# ballast register map
Vendor: tuni.fi; File version: 1.0
CPU: other, little endian, MPU, FPU, vendor SysTick, 3 interrupt priority bits
Registers are 32-bit, read-write, no defined reset value unless marked. A register's access mark holds for its fields unless they carry their own. Offsets are from the block's base; [hi:lo] are bit positions; lines under a group give offsets from that group; {n}, {i} and the like mark numbered series; 'fields as' and 'values as' point back to an identical list.

## AI
Base 0x10F000000
0x00 CFGROM group
  0x00 HW_VERSION_0 ro reset 0x10001
    [31:0] HW_VERSION
  0x04 GLB_DESC_0 ro reset 0x1
    [31:0] GLB_DESC
  0x08 CIF_DESC_0 ro reset 0x180002 (reset mask 0x7FFFFFF)
    [31:0] CIF_DESC
  0x0C CIF_CAP_INCOMPAT_0 ro reset 0x0
    [31:0] CIF_CAP_INCOMPAT
  0x10 CIF_CAP_COMPAT_0 ro reset 0x0 (reset mask 0x1FFF)
    [31:0] CIF_CAP_COMPAT
  0x14 CIF_BASE_WIDTH_0 ro reset 0x8 (reset mask 0xF)
    [7:0] CIF_BASE_WIDTH
  0x18 CIF_BASE_LATENCY_0 ro reset 0x32 (reset mask 0xFFFF)
    [31:0] CIF_BASE_LATENCY
  0x1C CIF_BASE_BURST_LENGTH_MAX_0 ro reset 0x80 (reset mask 0x1FE0)
    [31:5] BASE_BURST_LENGTH_MAX
  0x20 CIF_BASE_MEM_ADDR_WIDTH_0 ro reset 0x400 (reset mask 0x1FE0)
    [31:5] CIF_BASE_MEM_ADDR_WIDTH
  0x24 CDMA_DESC_0 ro reset 0x340003
    [31:0] CDMA_DESC
  0x28 CDMA_CAP_INCOMPAT_0 ro reset 0x0
    [31:0] CDMA_CAP_INCOMPAT
  0x2C CDMA_CAP_COMPAT_0 ro reset 0x10
    [31:0] CDMA_CAP_COMPAT
  0x30 CDMA_BASE_FEATURE_TYPES_0 ro reset 0x10
    [11:0] CDMA_BASE_FEATURE_TYPES
  0x34 CDMA_BASE_WEIGHT_TYPES_0 ro reset 0x10
    [11:0] CDMA_BASE_WEIGHT_TYPES
  0x38 CDMA_BASE_ATOMIC_C_0 ro reset 0x8 (reset mask 0xFF)
    [31:0] CDMA_BASE_ATOMIC_C
  0x3C CDMA_BASE_ATOMIC_K_0 ro reset 0x8 (reset mask 0xFF)
    [31:0] CDMA_BASE_ATOMIC_K
  0x40 CDMA_BASE_ATOMIC_M_0 ro reset 0x8 (reset mask 0xFF)
    [31:0] CDMA_BASE_ATOMIC_M
  0x44 CDMA_BASE_CBUF_BANK_NUM_0 ro reset 0x20
    [31:0] CDMA_BASE_CBUF_BANK_NUM
  0x48 CDMA_BASE_CBUF_BANK_WIDTH_0 ro reset 0x8
    [31:0] CDMA_BASE_CBUF_BANK_WIDTH
  0x4C CDMA_BASE_CBUF_BANK_DEPTH_0 ro reset 0x200
    [31:0] CDMA_BASE_CBUF_BANK_DEPTH
  0x50 CDMA_MULTI_BATCH_MAX_0 ro reset 0x0
    [31:0] CDMA_MULTI_BATCH_MAX
  0x54 CDMA_IMAGE_IN_FORMATS_PACKED_0 ro reset 0xCFFF001
    [31:0] CDMA_IMAGE_IN_FORMATS_PACKED
  0x58 CDMA_IMAGE_IN_FORMATS_SEMI_0 ro reset 0x3
    [31:0] CDMA_IMAGE_IN_FORMATS_SEMI
  0x5C CBUF_DESC_0 ro reset 0x180004
    [31:0] CBUF_DESC
  0x60 CBUF_CAP_INCOMPAT_0 ro reset 0x0
    [31:0] CBUF_CAP_INCOMPAT
  0x64 CBUF_CAP_COMPAT_0 ro reset 0x0
    [31:0] CBUF_CAP_COMPAT
  0x68 CBUF_BASE_CBUF_BANK_NUM_0 ro reset 0x20
    [31:0] CBUF_BASE_CBUF_BANK_NUM
  0x6C CBUF_BASE_CBUF_BANK_WIDTH_0 ro reset 0x8
    [31:0] CBUF_BASE_CBUF_BANK_WIDTH
  0x70 CBUF_BASE_CBUF_BANK_DEPTH_0 ro reset 0x200
    [31:0] CBUF_BASE_CBUF_BANK_DEPTH
  0x74 CBUF_BASE_CDMA_ID_0 ro reset 0x3
    [31:0] CBUF_BASE_CDMA_ID
  0x78 CSC_DESC_0 ro reset 0x300005
    [31:0] CSC_DESC
  0x7C CSC_CAP_INCOMPAT_0 ro reset 0x0
    [31:0] CSC_CAP_INCOMPAT
  0x80 CSC_CAP_COMPAT_0 ro reset 0x10
    [31:0] CSC_CAP_COMPAT
  0x84 CSC_BASE_FEATURE_TYPES_0 ro reset 0x10
    [11:0] CSC_BASE_FEATURE_TYPES
  0x88 CSC_BASE_WEIGHT_TYPES_0 ro reset 0x10
    [11:0] CSC_BASE_WEIGHT_TYPES
  0x8C CSC_BASE_ATOMIC_C_0 ro reset 0x8 (reset mask 0xFF)
    [31:0] CSC_BASE_ATOMIC_C
  0x90 CSC_BASE_ATOMIC_K_0 ro reset 0x8 (reset mask 0xFF)
    [31:0] CSC_BASE_ATOMIC_K
  0x94 CSC_BASE_ATOMIC_M_0 ro reset 0x8 (reset mask 0xFF)
    [31:0] CSC_BASE_ATOMIC_M
  0x98 CSC_BASE_CBUF_BANK_NUM_0 ro reset 0x20
    [31:0] CSC_BASE_CBUF_BANK_NUM
  0x9C CSC_BASE_CBUF_BANK_WIDTH_0 ro reset 0x8
    [31:0] CSC_BASE_CBUF_BANK_WIDTH
  0xA0 CSC_BASE_CBUF_BANK_DEPTH_0 ro reset 0x200
    [31:0] CSC_BASE_CBUF_BANK_DEPTH
  0xA4 CSC_BASE_CDMA_ID_0 ro reset 0x3
    [31:0] CSC_BASE_CDMA_ID
  0xA8 CSC_MULTI_BATCH_MAX_0 ro reset 0x0
    [31:0] CSC_MULTI_BATCH_MAX
  0xAC CMAC_A_DESC_0 ro reset 0x1C0006
    [31:0] CMAC_A_DESC
  0xB0 CMAC_A_CAP_INCOMPAT_0 ro reset 0x0
    [31:0] CMAC_A_CAP_INCOMPAT
  0xB4 CMAC_A_CAP_COMPAT_0 ro reset 0x10
    [31:0] CMAC_A_CAP_COMPAT
  0xB8 CMAC_A_BASE_FEATURE_TYPES_0 ro reset 0x10
    [11:0] CMAC_A_BASE_FEATURE_TYPES
  0xBC CMAC_A_BASE_WEIGHT_TYPES_0 ro reset 0x10
    [11:0] CMAC_A_BASE_WEIGHT_TYPES
  0xC0 CMAC_A_BASE_ATOMIC_C_0 ro reset 0x8 (reset mask 0xFF)
    [31:0] CMAC_A_BASE_ATOMIC_C
  0xC4 CMAC_A_BASE_ATOMIC_K_0 ro reset 0x8 (reset mask 0xFF)
    [31:0] CMAC_A_BASE_ATOMIC_K
  0xC8 CMAC_A_BASE_CDMA_ID_0 ro reset 0x3
    [31:0] CMAC_A_BASE_CDMA_ID
  0xCC CMAC_B_DESC_0 ro reset 0x1C0006
    [31:0] CMAC_B_DESC
  0xD0 CMAC_B_CAP_INCOMPAT_0 ro reset 0x0
    [31:0] CMAC_B_CAP_INCOMPAT
  0xD4 CMAC_B_CAP_COMPAT_0 ro reset 0x10
    [31:0] CMAC_B_CAP_COMPAT
  0xD8 CMAC_B_BASE_FEATURE_TYPES_0 ro reset 0x10
    [11:0] CMAC_B_BASE_FEATURE_TYPES
  0xDC CMAC_B_BASE_WEIGHT_TYPES_0 ro reset 0x10
    [11:0] CMAC_B_BASE_WEIGHT_TYPES
  0xE0 CMAC_B_BASE_ATOMIC_C_0 ro reset 0x8 (reset mask 0xFF)
    [31:0] CMAC_B_BASE_ATOMIC_C
  0xE4 CMAC_B_BASE_ATOMIC_K_0 ro reset 0x8 (reset mask 0xFF)
    [31:0] CMAC_B_BASE_ATOMIC_K
  0xE8 CMAC_B_BASE_CDMA_ID_0 ro reset 0x3
    [31:0] CMAC_B_BASE_CDMA_ID
  0xEC CACC_DESC_0 ro reset 0x200007
    [31:0] CACC_DESC
  0xF0 CACC_CAP_INCOMPAT_0 ro reset 0x0
    [31:0] CACC_CAP_INCOMPAT
  0xF4 CACC_CAP_COMPAT_0 ro reset 0x0
    [31:0] CACC_CAP_COMPAT
  0xF8 CACC_BASE_FEATURE_TYPES_0 ro reset 0x10
    [11:0] CACC_BASE_FEATURE_TYPES
  0xFC CACC_BASE_WEIGHT_TYPES_0 ro reset 0x10
    [11:0] CACC_BASE_WEIGHT_TYPES
  0x100 CACC_BASE_ATOMIC_C_0 ro reset 0x8 (reset mask 0xFF)
    [31:0] CACC_BASE_ATOMIC_C
  0x104 CACC_BASE_ATOMIC_K_0 ro reset 0x8 (reset mask 0xFF)
    [31:0] CACC_BASE_ATOMIC_K
  0x108 CACC_BASE_CDMA_ID_0 ro reset 0x3
    [31:0] CACC_BASE_CDMA_ID
  0x10C CACC_MULTI_BATCH_MAX_0 ro reset 0x0
    [31:0] CACC_MULTI_BATCH_MAX
  0x110 SDP_RDMA_DESC_0 ro reset 0xE0008
    [31:0] SDP_RDMA_DESC
  0x114 SDP_RDMA_CAP_INCOMPAT_0 ro reset 0x0
    [31:0] SDP_RDMA_CAP_INCOMPAT
  0x118 SDP_RDMA_CAP_COMPAT_0 ro reset 0x0
    [31:0] SDP_RDMA_CAP_COMPAT
  0x11C SDP_RDMA_BASE_ATOMIC_M_0 ro reset 0x8 (reset mask 0xFF)
    [31:0] SDP_RDMA_BASE_ATOMIC_M
  0x120 SDP_RDMA_BASE_SDP_ID_0 ro reset 0x9
    [31:0] SDP_RDMA_BASE_SDP_ID
  0x124 SDP_DESC_0 ro reset 0x200009
    [31:0] SDP_DESC
  0x128 SDP_CAP_INCOMPAT_0 ro reset 0x0
    [31:0] SDP_CAP_INCOMPAT
  0x12C SDP_CAP_COMPAT_0 ro reset 0x18
    [31:0] SDP_CAP_COMPAT
  0x130 SDP_BASE_FEATURE_TYPES_0 ro reset 0x10
    [11:0] SDP_BASE_FEATURE_TYPES
  0x134 SDP_BASE_WEIGHT_TYPES_0 ro reset 0x10
    [11:0] SDP_BASE_WEIGHT_TYPES
  0x138 SDP_BASE_CDMA_ID_0 ro reset 0x3
    [31:0] SDP_BASE_CDMA_ID
  0x13C SDP_MULTI_BATCH_MAX_0 ro reset 0x0
    [31:0] SDP_MULTI_BATCH_MAX
  0x140 SDP_BS_THROUGHPUT_0 ro reset 0x1
    [31:0] SDP_BS_THROUGHPUT
  0x144 SDP_BN_THROUGHPUT_0 ro reset 0x1
    [31:0] SDP_BN_THROUGHPUT
  0x148 SDP_EW_THROUGHPUT_0 ro reset 0x0
    [31:0] SDP_EW_THROUGHPUT
  0x14C PDP_RDMA_DESC_0 ro reset 0xE000A
    [31:0] PDP_RDMA_DESC
  0x150 PDP_RDMA_CAP_INCOMPAT_0 ro reset 0x0
    [31:0] PDP_RDMA_CAP_INCOMPAT
  0x154 PDP_RDMA_CAP_COMPAT_0 ro reset 0x0
    [31:0] PDP_RDMA_CAP_COMPAT
  0x158 PDP_RDMA_BASE_ATOMIC_M_0 ro reset 0x8 (reset mask 0xFF)
    [31:0] PDP_RDMA_BASE_ATOMIC_M
  0x15C PDP_RDMA_BASE_PDP_ID_0 ro reset 0xB
    [31:0] PDP_RDMA_BASE_PDP_ID
  0x160 PDP_DESC_0 ro reset 0x10000B
    [31:0] PDP_DESC
  0x164 PDP_CAP_INCOMPAT_0 ro reset 0x0
    [31:0] PDP_CAP_INCOMPAT
  0x168 PDP_CAP_COMPAT_0 ro reset 0x0
    [31:0] PDP_CAP_COMPAT
  0x16C PDP_BASE_FEATURE_TYPES_0 ro reset 0x10
    [11:0] PDP_BASE_FEATURE_TYPES
  0x170 PDP_BASE_THROUGHPUT_0 ro reset 0x1
    [31:0] PDP_BASE_THROUGHPUT
  0x174 CDP_RDMA_DESC_0 ro reset 0xE000C
    [31:0] CDP_RDMA_DESC
  0x178 CDP_RDMA_CAP_INCOMPAT_0 ro reset 0x0
    [31:0] CDP_RDMA_CAP_INCOMPAT
  0x17C CDP_RDMA_CAP_COMPAT_0 ro reset 0x0
    [31:0] CDP_RDMA_CAP_COMPAT
  0x180 CDP_RDMA_BASE_ATOMIC_M_0 ro reset 0x8 (reset mask 0xFF)
    [31:0] CDP_RDMA_BASE_ATOMIC_M
  0x184 CDP_RDMA_BASE_CDP_ID_0 ro reset 0xD
    [31:0] CDP_RDMA_BASE_CDP_ID
  0x188 CDP_DESC_0 ro reset 0x10000D
    [31:0] CDP_DESC
  0x18C CDP_CAP_INCOMPAT_0 ro reset 0x0
    [31:0] CDP_CAP_INCOMPAT
  0x190 CDP_CAP_COMPAT_0 ro reset 0x0
    [31:0] CDP_CAP_COMPAT
  0x194 CDP_BASE_FEATURE_TYPES_0 ro reset 0x10
    [11:0] CDP_BASE_FEATURE_TYPES
  0x198 CDP_BASE_THROUGHPUT_0 ro reset 0x1
    [31:0] CDP_BASE_THROUGHPUT
  0x19C END_OF_LIST_0 ro reset 0x0
    [31:0] END_OF_LIST
0x1000 GLB group
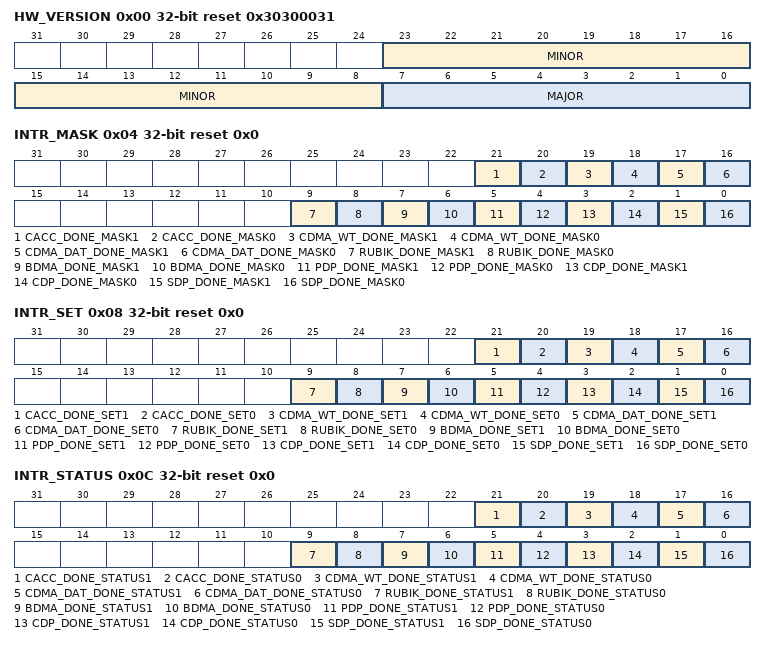
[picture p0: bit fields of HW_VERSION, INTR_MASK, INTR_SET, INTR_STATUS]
  0x00 HW_VERSION ro reset 0x30300031 (reset mask 0xFFFF00FF) — HW version of NVDLA
    [23:8] MINOR, [7:0] MAJOR
  0x04 INTR_MASK reset 0x0 (reset mask 0xFC000C03) — Interrupt mask control
    [21] CACC_DONE_MASK1 rw-once, [20] CACC_DONE_MASK0 rw-once, [19] CDMA_WT_DONE_MASK1 rw-once, [18] CDMA_WT_DONE_MASK0 rw-once, [17] CDMA_DAT_DONE_MASK1 rw-once, [16] CDMA_DAT_DONE_MASK0 rw-once, [9] RUBIK_DONE_MASK1 rw-once, [8] RUBIK_DONE_MASK0 rw-once, [7] BDMA_DONE_MASK1 rw-once, [6] BDMA_DONE_MASK0 rw-once, [5] PDP_DONE_MASK1 rw-once, [4] PDP_DONE_MASK0 rw-once, [3] CDP_DONE_MASK1 rw-once, [2] CDP_DONE_MASK0 rw-once, [1] SDP_DONE_MASK1 rw-once, [0] SDP_DONE_MASK0 rw-once
  0x08 INTR_SET wo reset 0x0 (reset mask 0xFC000C03) — Interrupt set control
    [21] CACC_DONE_SET1, [20] CACC_DONE_SET0, [19] CDMA_WT_DONE_SET1, [18] CDMA_WT_DONE_SET0, [17] CDMA_DAT_DONE_SET1, [16] CDMA_DAT_DONE_SET0, [9] RUBIK_DONE_SET1, [8] RUBIK_DONE_SET0, [7] BDMA_DONE_SET1, [6] BDMA_DONE_SET0, [5] PDP_DONE_SET1, [4] PDP_DONE_SET0, [3] CDP_DONE_SET1, [2] CDP_DONE_SET0, [1] SDP_DONE_SET1, [0] SDP_DONE_SET0
  0x0C INTR_STATUS reset 0x0 (reset mask 0xFC000C03) — Interrupt status
    [21] CACC_DONE_STATUS1 rw-once, [20] CACC_DONE_STATUS0 rw-once, [19] CDMA_WT_DONE_STATUS1 rw-once, [18] CDMA_WT_DONE_STATUS0 rw-once, [17] CDMA_DAT_DONE_STATUS1 rw-once, [16] CDMA_DAT_DONE_STATUS0 rw-once, [9] RUBIK_DONE_STATUS1 rw-once, [8] RUBIK_DONE_STATUS0 rw-once, [7] BDMA_DONE_STATUS1 rw-once, [6] BDMA_DONE_STATUS0 rw-once, [5] PDP_DONE_STATUS1 rw-once, [4] PDP_DONE_STATUS0 rw-once, [3] CDP_DONE_STATUS1 rw-once, [2] CDP_DONE_STATUS0 rw-once, [1] SDP_DONE_STATUS1 rw-once, [0] SDP_DONE_STATUS0 rw-once
0x2000 MCIF group
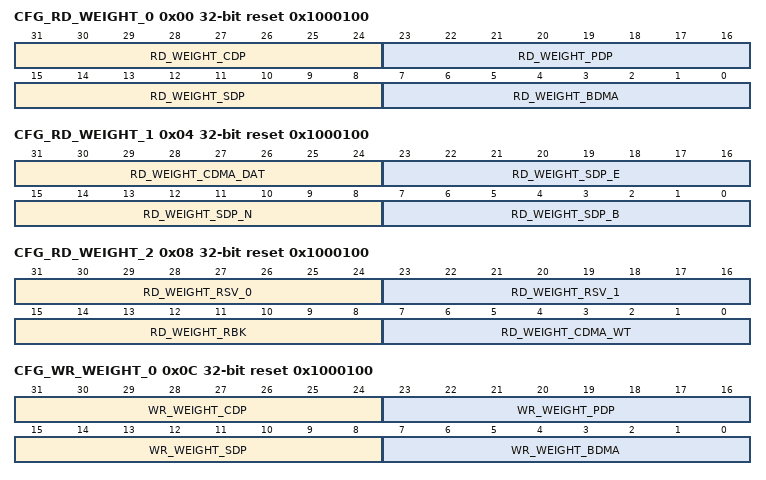
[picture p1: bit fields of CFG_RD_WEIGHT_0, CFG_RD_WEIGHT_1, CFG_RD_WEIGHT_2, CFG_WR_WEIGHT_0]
  0x00 CFG_RD_WEIGHT_0 reset 0x1000100 (reset mask 0xFF00FF00) — Register0 to control the read weight of clients in MCIF
    [31:24] RD_WEIGHT_CDP ro, [23:16] RD_WEIGHT_PDP ro, [15:8] RD_WEIGHT_SDP ro, [7:0] RD_WEIGHT_BDMA ro
  0x04 CFG_RD_WEIGHT_1 reset 0x1000100 (reset mask 0xFF00FF00) — Register1 to control the read weight of clients in MCIF
    [31:24] RD_WEIGHT_CDMA_DAT ro, [23:16] RD_WEIGHT_SDP_E ro, [15:8] RD_WEIGHT_SDP_N ro, [7:0] RD_WEIGHT_SDP_B ro
  0x08 CFG_RD_WEIGHT_2 reset 0x1000100 (reset mask 0xFF00FF00) — Register2 to control the read weight of clients in MCIF
    [31:24] RD_WEIGHT_RSV_0 ro, [23:16] RD_WEIGHT_RSV_1 ro, [15:8] RD_WEIGHT_RBK ro, [7:0] RD_WEIGHT_CDMA_WT ro
  0x0C CFG_WR_WEIGHT_0 reset 0x1000100 (reset mask 0xFF00FF00) — Register0 to control the write weight of clients in MCIF
    [31:24] WR_WEIGHT_CDP ro, [23:16] WR_WEIGHT_PDP ro, [15:8] WR_WEIGHT_SDP ro, [7:0] WR_WEIGHT_BDMA ro
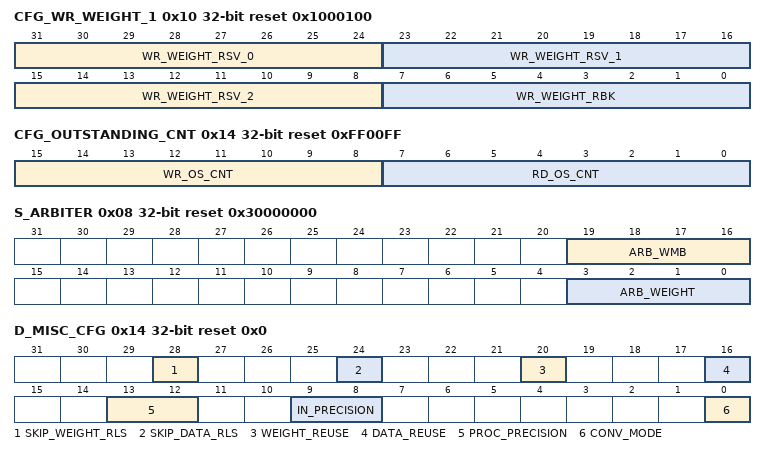
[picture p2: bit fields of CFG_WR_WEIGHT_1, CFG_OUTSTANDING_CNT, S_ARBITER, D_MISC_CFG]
  0x10 CFG_WR_WEIGHT_1 reset 0x1000100 (reset mask 0xFF00FF00) — Register1 to control the write weight of clients in MCIF
    [31:24] WR_WEIGHT_RSV_0 ro, [23:16] WR_WEIGHT_RSV_1 ro, [15:8] WR_WEIGHT_RSV_2 ro, [7:0] WR_WEIGHT_RBK ro
  0x14 CFG_OUTSTANDING_CNT reset 0xFF00FF (reset mask 0xFF00FF) — Outstanding AXI transactions in unit of 64Byte
    [15:8] WR_OS_CNT ro, [7:0] RD_OS_CNT ro
  0x18 STATUS ro reset 0x10000 (reset mask 0x10000) — Idle status of MCIF
    [8] IDLE
      0=NO; 1=YES
0x3000 CDMA group
  0x00 S_STATUS ro reset 0x0 (reset mask 0xC0000000) — Idle status of two register groups
    [17:16] STATUS_1
      1=RUNNING; 2=PENDING; 0=IDLE
    [1:0] STATUS_0
      0=IDLE; 1=RUNNING; 2=PENDING
  0x04 S_POINTER reset 0x0 (reset mask 0x80000000) — Pointer for CSB master and data path to access groups
    [16] CONSUMER ro
      1=GROUP_1; 0=GROUP_0
    [0] PRODUCER rw-once
      0=GROUP_0; 1=GROUP_1
  0x08 S_ARBITER reset 0x30000000 (reset mask 0xF0000000) — WMB and Weight share same port to access external memory. This register controls the weight factor in the arbiter.
    [19:16] ARB_WMB rw-once, [3:0] ARB_WEIGHT rw-once
  0x0C S_CBUF_FLUSH_STATUS ro reset 0x0 — Indicates whether CBUF flush is finished after reset.
    [0] FLUSH_DONE
  0x10 D_OP_ENABLE reset 0x0 — Set it to 1 to kick off operation for current register group
    [0] OP_EN rw-once
      0=DISABLE; 1=ENABLE
  0x14 D_MISC_CFG reset 0x0 (reset mask 0x88008801) — Configuration of operation: convolution mode, precision, weight reuse, data reuse.
    [28] SKIP_WEIGHT_RLS rw-once
      1=ENABLE; 0=DISABLE
    [24] SKIP_DATA_RLS rw-once
      1=ENABLE; 0=DISABLE
    [20] WEIGHT_REUSE rw-once
      1=ENABLE; 0=DISABLE
    [16] DATA_REUSE rw-once
      1=ENABLE; 0=DISABLE
    [13:12] PROC_PRECISION rw-once
      2=FP16; 1=INT16; 0=INT8
    [9:8] IN_PRECISION rw-once
      0=INT8; 1=INT16; 2=FP16
    [0] CONV_MODE rw-once
      0=DIRECT; 1=WINOGRAD
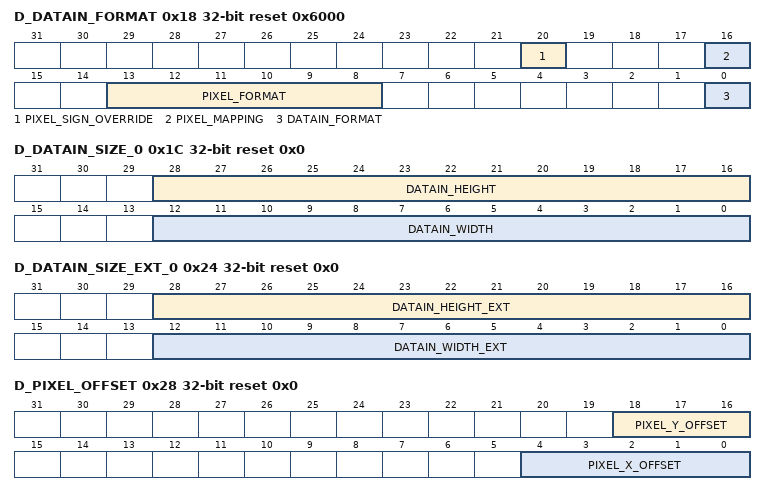
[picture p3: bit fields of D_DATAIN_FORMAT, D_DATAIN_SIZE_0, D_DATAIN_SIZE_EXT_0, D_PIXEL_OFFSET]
  0x18 D_DATAIN_FORMAT reset 0x6000 (reset mask 0x8801F800) — Input data format and pixel format
    [20] PIXEL_SIGN_OVERRIDE rw-once
      0=UNSIGNED_INT; 1=SIGNED_INT
    [16] PIXEL_MAPPING rw-once
      0=PITCH_LINEAR
    [13:8] PIXEL_FORMAT rw-once
      0=T_R8; 1=T_R10; 2=T_R12; 3=T_R16; 4=T_R16_I; 5=T_R16_F; 6=T_A16B16G16R16; 7=T_X16B16G16R16; 8=T_A16B16G16R16_F; 9=T_A16Y16U16V16; 10=T_V16U16Y16A16; 11=T_A16Y16U16V16_F; 12=T_A8B8G8R8; 31=T_Y10___V10U10_N444; 19=T_R8G8B8X8; 13=T_A8R8G8B8; 26=T_A8Y8U8V8; 18=T_B8G8R8X8; 32=T_Y12___U12V12_N444; 20=T_A2B10G10R10; 14=T_B8G8R8A8; 33=T_Y12___V12U12_N444; 21=T_A2R10G10B10; 15=T_R8G8B8A8; 34=T_Y16___U16V16_N444; 22=T_B10G10R10A2; 27=T_V8U8Y8A8; 16=T_X8B8G8R8; 35=T_Y16___V16U16_N444; 23=T_R10G10B10A2; 28=T_Y8___U8V8_N444; 29=T_Y8___V8U8_N444; 30=T_Y10___U10V10_N444; 17=T_X8R8G8B8; 24=T_A2Y10U10V10; 25=T_V10U10Y10A2
    [0] DATAIN_FORMAT rw-once
      1=PIXEL; 0=FEATURE
  0x1C D_DATAIN_SIZE_0 reset 0x0 (reset mask 0xFFF80000) — Input cube’s width and height
    [28:16] DATAIN_HEIGHT rw-once, [12:0] DATAIN_WIDTH rw-once
  0x20 D_DATAIN_SIZE_1 reset 0x0 — Input cube’s channel
    [12:0] DATAIN_CHANNEL rw-once
  0x24 D_DATAIN_SIZE_EXT_0 reset 0x0 (reset mask 0xFFF80000) — Input cube’s width and height after extension
    [28:16] DATAIN_HEIGHT_EXT, [12:0] DATAIN_WIDTH_EXT
  0x28 D_PIXEL_OFFSET reset 0x0 (reset mask 0xE0000003) — For image-in mode, horizontal offset and vertical offset of the 1 st pixel.
    [18:16] PIXEL_Y_OFFSET rw-once, [4:0] PIXEL_X_OFFSET rw-once
  0x2C D_DAIN_RAM_TYPE reset 0x0 — Ram type of input RAM
    [0] DATAIN_RAM_TYPE rw-once
      0=CVIF; 1=MCIF
  0x30 D_DAIN_ADDR_HIGH_0 reset 0x0 — Higher 32bits of input data address when axi araddr is 64bits
    [31:0] DATAIN_ADDR_HIGH_0 rw-once
  0x34 D_DAIN_ADDR_LOW_0 reset 0x0 — Lower 32bits of input data address
    [31:0] DATAIN_ADDR_LOW_0
  0x38 D_DAIN_ADDR_HIGH_1 reset 0x0 — Higher 32bits of input data address of UV plane when axi araddr is 64bits
    [31:0] DATAIN_ADDR_HIGH_1
  0x3C D_DAIN_ADDR_LOW_1 reset 0x0 — Lower 32bits of input data address of UV plane
    [31:0] DATAIN_ADDR_LOW_1
  0x40 D_LINE_STRIDE reset 0x0 — Line stride of input cube
    [31:0] LINE_STRIDE
  0x44 D_LINE_UV_STRIDE reset 0x0 — Line stride of input cube’s UV plane
    [31:0] UV_LINE_STRIDE
  0x48 D_SURF_STRIDE reset 0x0 — Surface stride of input cube
    [31:0] SURF_STRIDE
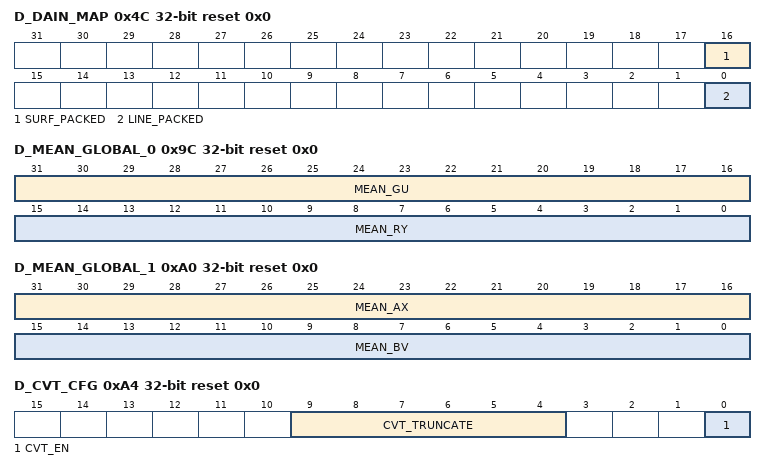
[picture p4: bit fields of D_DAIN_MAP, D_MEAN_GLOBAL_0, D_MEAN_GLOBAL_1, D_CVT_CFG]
  0x4C D_DAIN_MAP reset 0x0 (reset mask 0x80000000) — Whether input cube is line packed or surface packed
    [16] SURF_PACKED
      1=TRUE; 0=FALSE
    [0] LINE_PACKED
      0=FALSE; 1=TRUE
  0x58 D_BATCH_NUMBER reset 0x0 — Number of batches
    [4:0] BATCHES
  0x5C D_BATCH_STRIDE reset 0x0 — The stride of input data cubes when batches > 1
    [31:0] BATCH_STRIDE
  0x60 D_ENTRY_PER_SLICE reset 0x0 — Number of CBUF entries used for one input slice
    [13:0] ENTRIES
  0x64 D_FETCH_GRAIN reset 0x0 — Number of slices to be fetched before sending update information to CSC
    [11:0] GRAINS
  0x68 D_WEIGHT_FORMAT reset 0x0 — Whether weight is compressed or not
    [0] WEIGHT_FORMAT
      1=COMPRESSED; 0=UNCOMPRESSED
  0x6C D_WEIGHT_SIZE_0 reset 0x0 — The size of one kernel in bytes
    [17:0] BYTE_PER_KERNEL
  0x70 D_WEIGHT_SIZE_1 reset 0x0 — Number of kernels
    [12:0] WEIGHT_KERNEL
  0x74 D_WEIGHT_RAM_TYPE reset 0x0 — Ram type of weight
    [0] WEIGHT_RAM_TYPE
      1=MCIF; 0=CVIF
  0x78 D_WEIGHT_ADDR_HIGH reset 0x0 — Higher 32bits of weight address when axi araddr is 64bits
    [31:0] WEIGHT_ADDR_HIGH
  0x7C D_WEIGHT_ADDR_LOW reset 0x0 — Lower 32bits of weight address
    [31:0] WEIGHT_ADDR_LOW
  0x80 D_WEIGHT_BYTES reset 0x0 (reset mask 0x1FFFFFF) — Total bytes of Weight
    [31:0] WEIGHT_BYTES
  0x84 D_WGS_ADDR_HIGH reset 0x0 — Higher 32bits of wgs address when axi araddr is 64bits
    [31:0] WGS_ADDR_HIGH
  0x88 D_WGS_ADDR_LOW reset 0x0 — Lower 32bits of wgs address
    [31:0] WGS_ADDR_LOW
  0x8C D_WMB_ADDR_HIGH reset 0x0 — Higher 32bits of wmb address when axi araddr is 64bits
    [31:0] WMB_ADDR_HIGH
  0x90 D_WMB_ADDR_LOW reset 0x0 — Lower 32bits of wmb address
    [31:0] WMB_ADDR_LOW
  0x94 D_WMB_BYTES reset 0x0 (reset mask 0x1FFFFF) — Total bytes of WMB
    [27:0] WMB_BYTES
  0x98 D_MEAN_FORMAT reset 0x0 — Whether mean registers are used or not
    [0] MEAN_FORMAT
      1=ENABLE; 0=DISABLE
  0x9C D_MEAN_GLOBAL_0 reset 0x0 (reset mask 0xFFFF0000) — Global mean value for red in RGB or Y in YUV Global mean value for green in RGB or U in YUV
    [31:16] MEAN_GU, [15:0] MEAN_RY
  0xA0 D_MEAN_GLOBAL_1 reset 0x0 (reset mask 0xFFFF0000) — Global mean value for blue in RGB or V in YUV Global mean value for alpha in ARGB/AYUV or X in XRGB
    [31:16] MEAN_AX, [15:0] MEAN_BV
  0xA4 D_CVT_CFG reset 0x0 — Enable/disable input data converter in CDMA and number of bits to be truncated in the input data converter
    [9:4] CVT_TRUNCATE
    [0] CVT_EN
      1=ENABLE; 0=DISABLE
  0xA8 D_CVT_OFFSET reset 0x0 — Offset of input data convertor
    [15:0] CVT_OFFSET
  0xAC D_CVT_SCALE reset 0x0 — Scale of input data convertor
    [15:0] CVT_SCALE
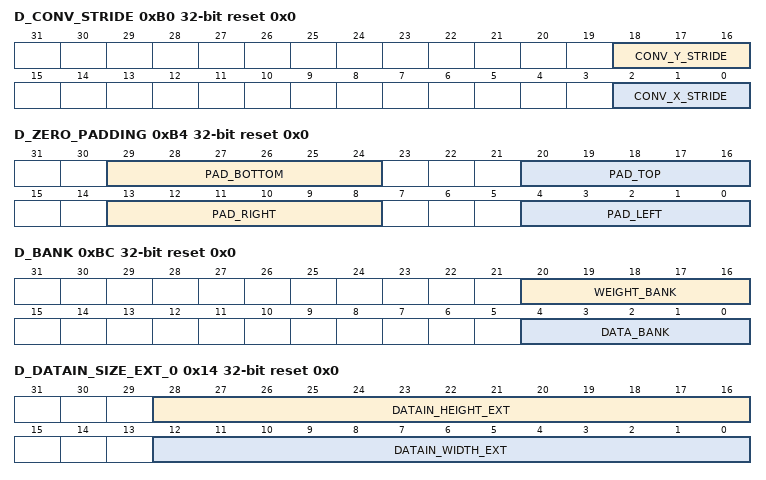
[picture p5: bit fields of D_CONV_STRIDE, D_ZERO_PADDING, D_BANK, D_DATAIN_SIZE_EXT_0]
  0xB0 D_CONV_STRIDE reset 0x0 (reset mask 0xE0000000) — Convolution x stride and convolution y stride
    [18:16] CONV_Y_STRIDE, [2:0] CONV_X_STRIDE
  0xB4 D_ZERO_PADDING reset 0x0 (reset mask 0xFC007C00) — Left/right/top/bottom padding size
    [29:24] PAD_BOTTOM, [20:16] PAD_TOP, [13:8] PAD_RIGHT, [4:0] PAD_LEFT
  0xB8 D_ZERO_PADDING_VALUE reset 0x0 — Padding value
    [15:0] PAD_VALUE
  0xBC D_BANK reset 0x0 (reset mask 0xF8000000) — Number of data banks and weight banks in CBUF
    [20:16] WEIGHT_BANK, [4:0] DATA_BANK
  0xC0 D_NAN_FLUSH_TO_ZERO ro reset 0x0 — Enable/Disable flushing input NaN to zero
    [0] NAN_TO_ZERO
      1=ENABLE; 0=DISABLE
  0xC4 D_NAN_INPUT_DATA_NUM ro reset 0x0 — Count NaN number in input data cube, update per layer
    [31:0] NAN_DATA_NUM
  0xC8 D_NAN_INPUT_WEIGHT_NUM ro reset 0x0 — Count NaN number in weight kernels, update per layer
    [31:0] NAN_WEIGHT_NUM
  0xCC D_INF_INPUT_DATA_NUM ro reset 0x0 — Count infinity number in input data cube, update per layer
    [31:0] INF_DATA_NUM
  0xD0 D_INF_INPUT_WEIGHT_NUM ro reset 0x0 — Count infinity number in weight kernels, update per layer
    [31:0] INF_WEIGHT_NUM
  0xD4 D_PERF_ENABLE reset 0x0 — Enable/disable performance counter
    [0] DMA_EN
  0xD8 D_PERF_DAT_READ_STALL ro reset 0x0 — Count blocking cycles of read request of input data, update per layer
    [31:0] DAT_RD_STALL
  0xDC D_PERF_WT_READ_STALL ro reset 0x0 — Count blocking cycles of read request of weight data, update per layer
    [31:0] WT_RD_STALL
  0xE0 D_PERF_DAT_READ_LATENCY ro reset 0x0 — Count total latency cycles of read response of input data, update per layer
    [31:0] DAT_RD_LATENCY
  0xE4 D_PERF_WT_READ_LATENCY ro reset 0x0 — Count total latency cycles of read request of weight data, update per layer
    [31:0] WT_RD_LATENCY
  0xE8 D_CYA reset 0x0
    [31:0] D_CYA — CYA register
0x4000 CSC group
  0x00 S_STATUS ro reset 0x0 (reset mask 0xC0000000) — Idle status of two register groups
    [17:16] STATUS_1
      1=RUNNING; 2=PENDING; 0=IDLE
    [1:0] STATUS_0
      1=RUNNING; 2=PENDING; 0=IDLE
  0x04 S_POINTER reset 0x0 (reset mask 0x80000000) — Pointer for CSB master and data path to access groups
    [16] CONSUMER ro
      1=GROUP_1; 0=GROUP_0
    [0] PRODUCER
      1=GROUP_1; 0=GROUP_0
  0x08 D_OP_ENABLE reset 0x0 — Set it to 1 to kick off operation for current register group
    [0] OP_EN
      1=ENABLE; 0=DISABLE
  0x0C D_MISC_CFG reset 0x0 (reset mask 0x88008801) — Configuration of operation: convolution mode, precision, weight reuse, data reuse.
    [28] SKIP_WEIGHT_RLS
      1=ENABLE; 0=DISABLE
    [24] SKIP_DATA_RLS
      1=ENABLE; 0=DISABLE
    [20] WEIGHT_REUSE
      1=ENABLE; 0=DISABLE
    [16] DATA_REUSE
      1=ENABLE; 0=DISABLE
    [13:12] PROC_PRECISION
      2=FP16; 1=INT16; 0=INT8
    [9:8] IN_PRECISION
      2=FP16; 1=INT16; 0=INT8
    [0] CONV_MODE
      0=DIRECT; 1=WINOGRAD
  0x10 D_DATAIN_FORMAT reset 0x0 — Input data format and pixel format
    [0] DATAIN_FORMAT
      1=PIXEL; 0=FEATURE
  0x14 D_DATAIN_SIZE_EXT_0 reset 0x0 (reset mask 0xFFF80000) — Input cube’s width and height after extension
    [28:16] DATAIN_HEIGHT_EXT, [12:0] DATAIN_WIDTH_EXT
  0x18 D_DATAIN_SIZE_EXT_1 reset 0x0 — Input cube’s channel after extension
    [12:0] DATAIN_CHANNEL_EXT
  0x1C D_BATCH_NUMBER reset 0x0 — Number of batches
    [4:0] BATCHES
  0x20 D_POST_Y_EXTENSION reset 0x0 — Post extension parameter for image-in
    [1:0] Y_EXTENSION
  0x24 D_ENTRY_PER_SLICE reset 0x0 — Number of CBUF entries used for one input slice
    [13:0] ENTRIES
  0x28 D_WEIGHT_FORMAT reset 0x0 — Whether weight is compressed or not
    [0] WEIGHT_FORMAT
      1=COMPRESSED; 0=UNCOMPRESSED
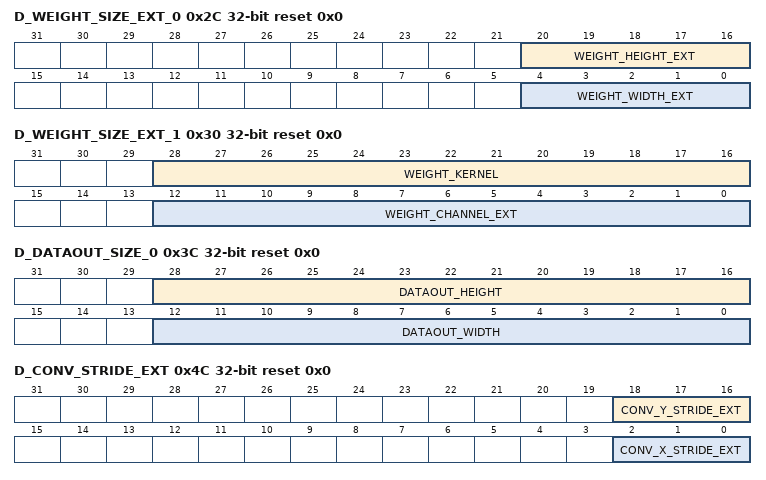
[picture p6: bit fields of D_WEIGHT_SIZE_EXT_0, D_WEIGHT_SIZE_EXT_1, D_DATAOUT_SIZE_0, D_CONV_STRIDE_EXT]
  0x2C D_WEIGHT_SIZE_EXT_0 reset 0x0 (reset mask 0xF8000000) — Weight’s width and height after extension
    [20:16] WEIGHT_HEIGHT_EXT, [4:0] WEIGHT_WIDTH_EXT
  0x30 D_WEIGHT_SIZE_EXT_1 reset 0x0 (reset mask 0xFFF80000) — Weight’s channel after extension and number of weight kernels
    [28:16] WEIGHT_KERNEL, [12:0] WEIGHT_CHANNEL_EXT
  0x34 D_WEIGHT_BYTES reset 0x0 (reset mask 0x1FFFFFF) — Total bytes of Weight
    [31:0] WEIGHT_BYTES
  0x38 D_WMB_BYTES reset 0x0 (reset mask 0x1FFFFF) — Total bytes of WMB
    [27:0] WMB_BYTES
  0x3C D_DATAOUT_SIZE_0 reset 0x0 (reset mask 0xFFF80000) — Output cube’s width and height
    [28:16] DATAOUT_HEIGHT, [12:0] DATAOUT_WIDTH
  0x40 D_DATAOUT_SIZE_1 reset 0x0 — Output cube’s channel
    [12:0] DATAOUT_CHANNEL
  0x44 D_ATOMICS reset 0x1 — Equals to output_data_cube_width * output_data_cube_height - 1
    [20:0] ATOMICS
  0x48 D_RELEASE reset 0x1 — Slices of CBUF to be released at the end of current layer
    [11:0] RLS_SLICES
  0x4C D_CONV_STRIDE_EXT reset 0x0 (reset mask 0xE0000000) — Convolution x stride and convolution y stride after extension
    [18:16] CONV_Y_STRIDE_EXT, [2:0] CONV_X_STRIDE_EXT
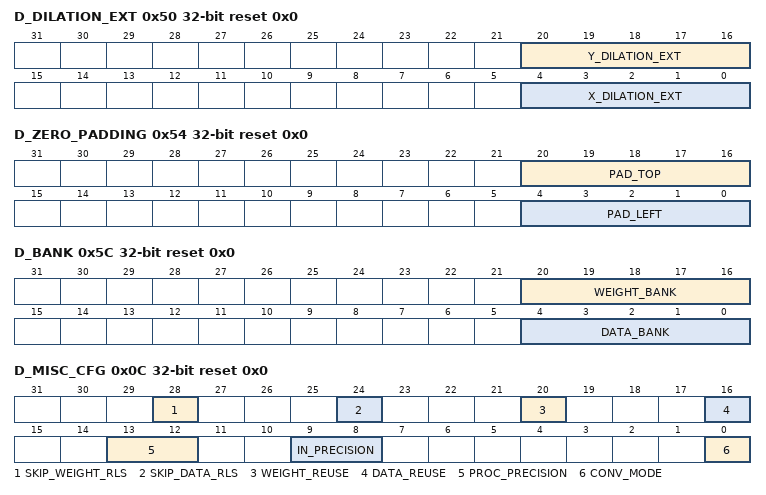
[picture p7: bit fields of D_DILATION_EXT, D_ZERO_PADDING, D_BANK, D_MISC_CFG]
  0x50 D_DILATION_EXT reset 0x0 (reset mask 0xF8000000) — Dilation parameter
    [20:16] Y_DILATION_EXT, [4:0] X_DILATION_EXT
  0x54 D_ZERO_PADDING reset 0x0 (reset mask 0xF8000000) — Left/right/top/bottom padding size
    [20:16] PAD_TOP, [4:0] PAD_LEFT
  0x58 D_ZERO_PADDING_VALUE reset 0x0 — Padding value
    [15:0] PAD_VALUE
  0x5C D_BANK reset 0x0 (reset mask 0xF8000000) — Number of data banks and weight banks in CBUF
    [20:16] WEIGHT_BANK, [4:0] DATA_BANK
  0x60 D_PRA_CFG reset 0x0 — PRA truncate in Winograd mode, range: 0~2
    [1:0] PRA_TRUNCATE
  0x64 D_CYA reset 0x0
    [31:0] D_CYA — CYA register
0x5000 CMAC_A group
  0x00 S_STATUS ro reset 0x0 (reset mask 0xC0000000) — Idle status of two register groups
    [17:16] STATUS_1
      0=IDLE; 1=RUNNING; 2=PENDING
    [1:0] STATUS_0
      0=IDLE; 1=RUNNING; 2=PENDING
  0x04 S_POINTER reset 0x0 (reset mask 0x80000000) — Pointer for CSB master and data path to access groups
    [16] CONSUMER ro
      0=GROUP_0; 1=GROUP_1
    [0] PRODUCER
      0=GROUP_0; 1=GROUP_1
  0x08 D_OP_ENABLE reset 0x0 — Set it to 1 to kick off operation for current register group
    [0] OP_EN
      1=ENABLE; 0=DISABLE
  0x0C D_MISC_CFG reset 0x100000 (reset mask 0x300001) — Configuration of operation: convolution mode, precision, etc.
    [13:12] PROC_PRECISION
      2=FP16; 1=INT16; 0=INT8
    [0] CONV_MODE
      0=DIRECT; 1=WINOGRAD
0x6000 CMAC_B group
  0x00 S_STATUS ro reset 0x0 (reset mask 0xC0000000) — Idle status of two register groups
    [17:16] STATUS_1
      1=ENABLE; 0=DISABLE
    [1:0] STATUS_0
      1=ENABLE; 0=DISABLE
  0x04 S_POINTER reset 0x0 (reset mask 0x80000000) — Pointer for CSB master and data path to access groups
    fields as CMAC_A.S_POINTER
  0x08 D_OP_ENABLE reset 0x0 — Set it to 1 to kick off operation for current register group
    [0] OP_EN
      1=ENABLE; 0=DISABLE
  0x0C D_MISC_CFG reset 0x100000 (reset mask 0x300001) — Configuration of operation: convolution mode, precision, etc.
    [13:12] PROC_PRECISION
      2=FP16; 1=INT16; 0=INT8
    [0] CONV_MODE
      1=WINOGRAD; 0=DIRECT
0x7000 CACC group
  0x00 S_STATUS ro reset 0x0 (reset mask 0xC0000000) — Idle status of two register groups
    fields as CMAC_A.S_STATUS
  0x04 S_POINTER reset 0x0 (reset mask 0x80000000) — Pointer for CSB master and data path to access groups
    fields as CMAC_A.S_POINTER
  0x08 D_OP_ENABLE reset 0x0 — Set it to 1 to kick off operation for current register group
    [0] OP_EN
      1=ENABLE; 0=DISABLE
  0x0C D_MISC_CFG reset 0x100000 (reset mask 0x300001) — Configuration of operation: convolution mode, precision, etc.
    fields as CMAC_B.D_MISC_CFG
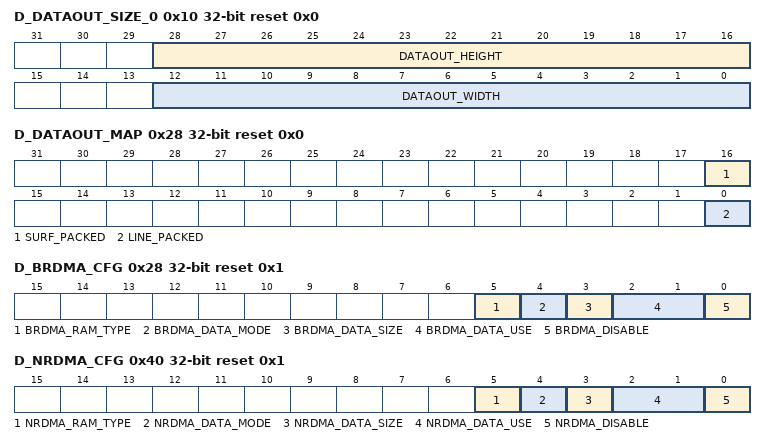
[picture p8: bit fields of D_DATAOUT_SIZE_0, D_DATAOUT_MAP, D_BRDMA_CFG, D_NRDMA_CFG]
  0x10 D_DATAOUT_SIZE_0 reset 0x0 (reset mask 0xFFF80000) — Input cube’s width and height after extension
    [28:16] DATAOUT_HEIGHT, [12:0] DATAOUT_WIDTH
  0x14 D_DATAOUT_SIZE_1 reset 0x0 — Input cube’s channel after extension
    [12:0] DATAOUT_CHANNEL
  0x18 D_DATAOUT_ADDR reset 0x0 — Address of output cube
    [31:0] DATAOUT_ADDR
  0x1C D_BATCH_NUMBER reset 0x0 — Number of batches
    [4:0] BATCHES
  0x20 D_LINE_STRIDE reset 0x0 — Line stride of output cube
    [23:0] LINE_STRIDE
  0x24 D_SURF_STRIDE reset 0x0 — Line stride of surface cube
    [23:0] SURF_STRIDE
  0x28 D_DATAOUT_MAP reset 0x0 (reset mask 0x80000000) — Whether output cube is line packed or surface packed
    [16] SURF_PACKED
      1=TRUE; 0=FALSE
    [0] LINE_PACKED
      1=TRUE; 0=FALSE
  0x2C D_CLIP_CFG reset 0x0 — Number of bits to be truncated before sending to SDP
    [4:0] CLIP_TRUNCATE
  0x30 D_OUT_SATURATION ro reset 0x0 — Output saturation count
    [31:0] SAT_COUNT
  0x34 D_CYA reset 0x0
    [31:0] D_CYA — CYA register
0x8000 SDP_RDMA group
  0x00 S_STATUS ro reset 0x0 (reset mask 0xC0000000) — Idle status of two register groups
    fields as CMAC_A.S_STATUS
  0x04 S_POINTER reset 0x0 (reset mask 0x80000000) — Pointer for CSB master and data path to access groups
    fields as CMAC_A.S_POINTER
  0x08 D_OP_ENABLE reset 0x0 — Set it to 1 to kick off operation for current register group
    [0] OP_EN
      1=ENABLE; 0=DISABLE
  0x0C D_DATA_CUBE_WIDTH reset 0x0
    [12:0] WIDTH
  0x10 D_DATA_CUBE_HEIGHT reset 0x0
    [12:0] HEIGHT
  0x14 D_DATA_CUBE_CHANNEL reset 0x0
    [12:0] CHANNEL
  0x18 D_SRC_BASE_ADDR_LOW reset 0x0
    [31:0] SRC_BASE_ADDR_LOW
  0x1C D_SRC_BASE_ADDR_HIGH reset 0x0
    [31:0] SRC_BASE_ADDR_HIGH
  0x20 D_SRC_LINE_STRIDE reset 0x0
    [31:0] SRC_LINE_STRIDE
  0x24 D_SRC_SURFACE_STRIDE reset 0x0
    [31:0] SRC_SURFACE_STRIDE
  0x28 D_BRDMA_CFG reset 0x1
    [5] BRDMA_RAM_TYPE
      0=CV; 1=MC
    [4] BRDMA_DATA_MODE
      0=PER_KERNEL; 1=PER_ELEMENT
    [3] BRDMA_DATA_SIZE
      0=ONE_BYTE; 1=TWO_BYTE
    [2:1] BRDMA_DATA_USE
      0=MUL; 1=ALU; 2=BOTH
    [0] BRDMA_DISABLE
      0=NO; 1=YES
  0x2C D_BS_BASE_ADDR_LOW reset 0x0
    [31:0] BS_BASE_ADDR_LOW
  0x30 D_BS_BASE_ADDR_HIGH reset 0x0
    [31:0] BS_BASE_ADDR_HIGH
  0x34 D_BS_LINE_STRIDE reset 0x0
    [31:0] BS_LINE_STRIDE
  0x38 D_BS_SURFACE_STRIDE reset 0x0
    [31:0] BS_SURFACE_STRIDE
  0x3C D_BS_BATCH_STRIDE reset 0x0
    [31:0] BS_BATCH_STRIDE
  0x40 D_NRDMA_CFG reset 0x1
    [5] NRDMA_RAM_TYPE
      1=MC; 0=CV
    [4] NRDMA_DATA_MODE
      0=PER_KERNEL; 1=PER_ELEMENT
    [3] NRDMA_DATA_SIZE
      1=TWO_BYTE; 0=ONE_BYTE
    [2:1] NRDMA_DATA_USE
      0=MUL; 2=BOTH; 1=ALU
    [0] NRDMA_DISABLE
      1=YES; 0=NO
  0x44 D_BN_BASE_ADDR_LOW reset 0x0
    [31:0] BN_BASE_ADDR_LOW
  0x48 D_BN_BASE_ADDR_HIGH reset 0x0
    [31:0] BN_BASE_ADDR_HIGH
  0x4C D_BN_LINE_STRIDE reset 0x0
    [31:0] BN_LINE_STRIDE
  0x50 D_BN_SURFACE_STRIDE reset 0x0
    [31:0] BN_SURFACE_STRIDE
  0x54 D_BN_BATCH_STRIDE reset 0x0
    [31:0] BN_BATCH_STRIDE
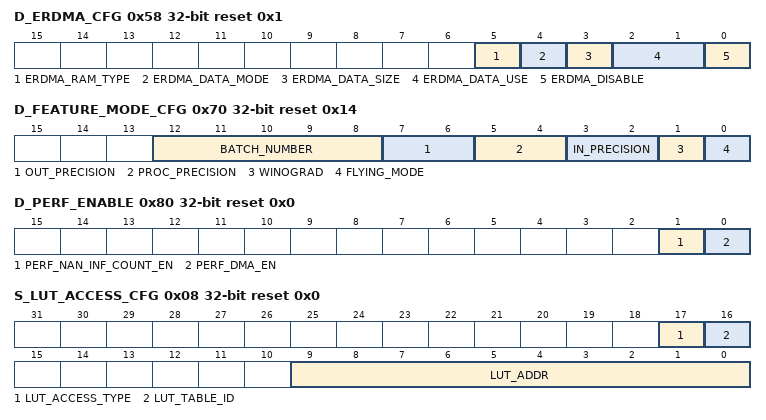
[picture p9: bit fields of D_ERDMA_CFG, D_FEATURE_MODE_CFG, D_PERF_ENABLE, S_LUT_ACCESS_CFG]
  0x58 D_ERDMA_CFG reset 0x1
    [5] ERDMA_RAM_TYPE
      1=MC; 0=CV
    [4] ERDMA_DATA_MODE
      0=PER_KERNEL; 1=PER_ELEMENT
    [3] ERDMA_DATA_SIZE
      1=TWO_BYTE; 0=ONE_BYTE
    [2:1] ERDMA_DATA_USE
      0=MUL; 2=BOTH; 1=ALU
    [0] ERDMA_DISABLE
      1=YES; 0=NO
  0x5C D_EW_BASE_ADDR_LOW reset 0x0
    [31:0] EW_BASE_ADDR_LOW
  0x60 D_EW_BASE_ADDR_HIGH reset 0x0
    [31:0] EW_BASE_ADDR_HIGH
  0x64 D_EW_LINE_STRIDE reset 0x0
    [31:0] EW_LINE_STRIDE
  0x68 D_EW_SURFACE_STRIDE reset 0x0
    [31:0] EW_SURFACE_STRIDE
  0x6C D_EW_BATCH_STRIDE reset 0x0
    [31:0] EW_BATCH_STRIDE
  0x70 D_FEATURE_MODE_CFG reset 0x14 (reset mask 0x1F00FF)
    [12:8] BATCH_NUMBER
    [7:6] OUT_PRECISION
      2=FP16; 1=INT16; 0=INT8
    [5:4] PROC_PRECISION
      2=FP16; 1=INT16; 0=INT8
    [3:2] IN_PRECISION
      2=FP16; 1=INT16; 0=INT8
    [1] WINOGRAD
      1=ON; 0=OFF
    [0] FLYING_MODE
      0=OFF; 1=ON
  0x74 D_SRC_DMA_CFG reset 0x0
    [0] SRC_RAM_TYPE
      1=MC; 0=CV
  0x78 D_STATUS_NAN_INPUT_NUM reset 0x0
    [31:0] STATUS_NAN_INPUT_NUM
  0x7C D_STATUS_INF_INPUT_NUM reset 0x0
    [31:0] STATUS_INF_INPUT_NUM
  0x80 D_PERF_ENABLE reset 0x0
    [1] PERF_NAN_INF_COUNT_EN
      1=YES; 0=NO
    [0] PERF_DMA_EN
      1=YES; 0=NO
  0x84 D_PERF_MRDMA_READ_STALL ro reset 0x0
    [31:0] MRDMA_STALL
  0x88 D_PERF_BRDMA_READ_STALL ro reset 0x0
    [31:0] BRDMA_STALL
  0x8C D_PERF_NRDMA_READ_STALL ro reset 0x0
    [31:0] NRDMA_STALL
  0x90 D_PERF_ERDMA_READ_STALL ro reset 0x0
    [31:0] ERDMA_STALL
0x9000 SDP group
  0x00 S_STATUS ro reset 0x0 (reset mask 0xC0000000) — Idle status of two register groups
    fields as CMAC_A.S_STATUS
  0x04 S_POINTER reset 0x0 (reset mask 0x80000000) — Pointer for CSB master and data path to access groups
    fields as CMAC_A.S_POINTER
  0x08 S_LUT_ACCESS_CFG reset 0x0 (reset mask 0xC00000FF) — LUT access address and type
    [17] LUT_ACCESS_TYPE
      0=READ; 1=WRITE
    [16] LUT_TABLE_ID
      0=LE; 1=LO
    [9:0] LUT_ADDR
  0x0C S_LUT_ACCESS_DATA reset 0x0 — Data register of read or write LUT
    [15:0] LUT_DATA
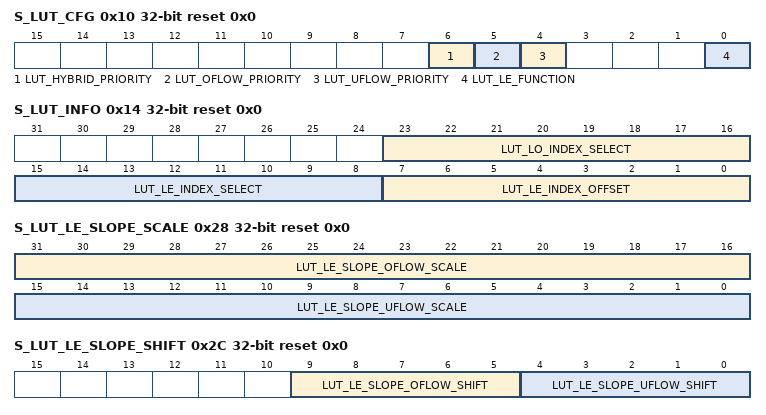
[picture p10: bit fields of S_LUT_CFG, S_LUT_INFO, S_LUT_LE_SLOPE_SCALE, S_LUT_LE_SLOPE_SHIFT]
  0x10 S_LUT_CFG reset 0x0 — LUT’s type: exponent or linear. And the selection between LE and LO tables.
    [6] LUT_HYBRID_PRIORITY
      1=LO; 0=LE
    [5] LUT_OFLOW_PRIORITY
      1=LO; 0=LE
    [4] LUT_UFLOW_PRIORITY
      1=LO; 0=LE
    [0] LUT_LE_FUNCTION
      0=EXPONENT; 1=LINEAR
  0x14 S_LUT_INFO reset 0x0 (reset mask 0xFF00FF00) — LE and LO LUT index offset and selection
    [23:16] LUT_LO_INDEX_SELECT, [15:8] LUT_LE_INDEX_SELECT, [7:0] LUT_LE_INDEX_OFFSET
  0x18 S_LUT_LE_START reset 0x0 — Start of LE LUT’s range
    [31:0] LUT_LE_START
  0x1C S_LUT_LE_END reset 0x0 — End of LE LUT’s range
    [31:0] LUT_LE_END
  0x20 S_LUT_LO_START reset 0x0 — Start of LO LUT’s range
    [31:0] LUT_LO_START
  0x24 S_LUT_LO_END reset 0x0 — End of LO LUT’s range
    [31:0] LUT_LO_END
  0x28 S_LUT_LE_SLOPE_SCALE reset 0x0 (reset mask 0xFFFF0000) — Slope scale parameter for LE LUT underflow and overflow, signed value
    [31:16] LUT_LE_SLOPE_OFLOW_SCALE, [15:0] LUT_LE_SLOPE_UFLOW_SCALE
  0x2C S_LUT_LE_SLOPE_SHIFT reset 0x0 — Slope shift parameter for LE_LUT underflow and overflow, signed value
    [9:5] LUT_LE_SLOPE_OFLOW_SHIFT, [4:0] LUT_LE_SLOPE_UFLOW_SHIFT
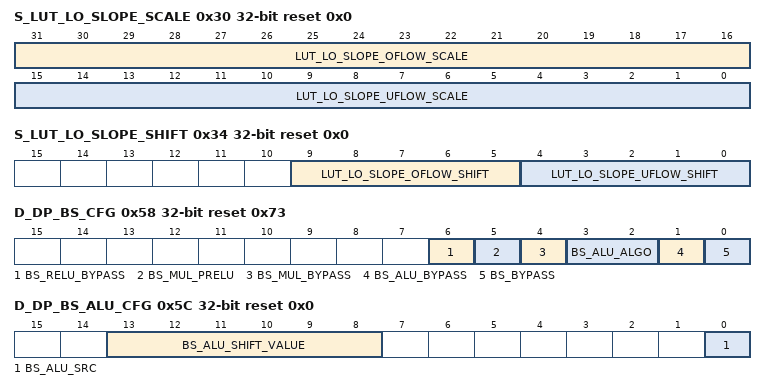
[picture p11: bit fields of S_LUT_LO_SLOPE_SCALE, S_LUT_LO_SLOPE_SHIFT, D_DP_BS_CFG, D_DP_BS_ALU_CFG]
  0x30 S_LUT_LO_SLOPE_SCALE reset 0x0 (reset mask 0xFFFF0000) — Slope scale parameter for LO LUT underflow and overflow, signed value
    [31:16] LUT_LO_SLOPE_OFLOW_SCALE, [15:0] LUT_LO_SLOPE_UFLOW_SCALE
  0x34 S_LUT_LO_SLOPE_SHIFT reset 0x0 — Slope shift parameter for LO_LUT underflow and overflow, signed value
    [9:5] LUT_LO_SLOPE_OFLOW_SHIFT, [4:0] LUT_LO_SLOPE_UFLOW_SHIFT
  0x38 D_OP_ENABLE reset 0x0 — Set it to 1 to kick off operation for current register group
    [0] OP_EN
      1=ENABLE; 0=DISABLE
  0x3C D_DATA_CUBE_WIDTH reset 0x0 — Input cube’s width
    [12:0] WIDTH
  0x40 D_DATA_CUBE_HEIGHT reset 0x0 — Input cube’s height
    [12:0] HEIGHT
  0x44 D_DATA_CUBE_CHANNEL reset 0x0 — Input cube’s channel
    [12:0] CHANNEL
  0x48 D_DST_BASE_ADDR_LOW ro reset 0x0 — Lower 32bits of output data address
    [31:0] DST_BASE_ADDR_LOW
  0x4C D_DST_BASE_ADDR_HIGH reset 0x0 — Higher 32bits of output data address when axi awaddr is 64bits
    [31:0] DST_BASE_ADDR_HIGH
  0x50 D_DST_LINE_STRIDE reset 0x0 — Line stride of output data cube
    [31:0] DST_LINE_STRIDE
  0x54 D_DST_SURFACE_STRIDE reset 0x0 — Surface stride of output data cube
    [31:0] DST_SURFACE_STRIDE
  0x58 D_DP_BS_CFG reset 0x73 — Configurations of BS module: bypass, algorithm, etc.
    [6] BS_RELU_BYPASS
      1=YES; 0=NO
    [5] BS_MUL_PRELU
      1=YES; 0=NO
    [4] BS_MUL_BYPASS
      1=YES; 0=NO
    [3:2] BS_ALU_ALGO
      0=MAX; 1=MIN; 2=SUM
    [1] BS_ALU_BYPASS
      1=YES; 0=NO
    [0] BS_BYPASS
      1=YES; 0=NO
  0x5C D_DP_BS_ALU_CFG reset 0x0 (reset mask 0x3F0001) — Source type and shifter value of BS ALU
    [13:8] BS_ALU_SHIFT_VALUE
    [0] BS_ALU_SRC
      0=REG; 1=MEM
  0x60 D_DP_BS_ALU_SRC_VALUE reset 0x0 — Operand value of BS ALU
    [15:0] BS_ALU_OPERAND
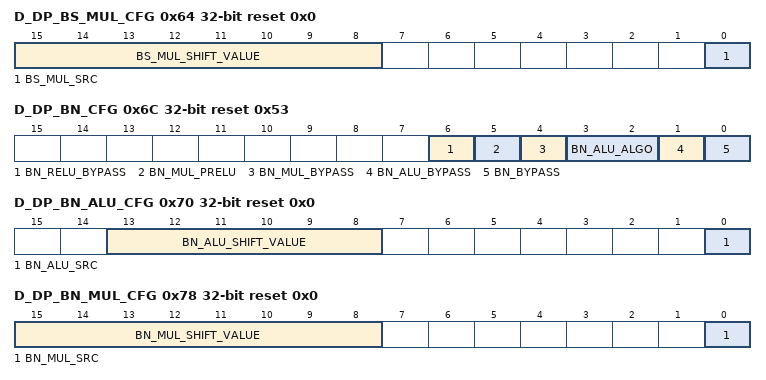
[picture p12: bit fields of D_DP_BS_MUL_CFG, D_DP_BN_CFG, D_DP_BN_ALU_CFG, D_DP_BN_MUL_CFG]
  0x64 D_DP_BS_MUL_CFG reset 0x0 (reset mask 0xFF0001) — Source type and shifter value of BS MUL
    [15:8] BS_MUL_SHIFT_VALUE
    [0] BS_MUL_SRC
      0=REG; 1=MEM
  0x68 D_DP_BS_MUL_SRC_VALUE reset 0x0 — Operand value of BS MUL
    [15:0] BS_MUL_OPERAND
  0x6C D_DP_BN_CFG reset 0x53 — Configurations of BN module: bypass, algorithm, etc.
    [6] BN_RELU_BYPASS
      1=YES; 0=NO
    [5] BN_MUL_PRELU
      1=YES; 0=NO
    [4] BN_MUL_BYPASS
      1=YES; 0=NO
    [3:2] BN_ALU_ALGO
      2=SUM; 1=MIN; 0=MAX
    [1] BN_ALU_BYPASS
      1=YES; 0=NO
    [0] BN_BYPASS
      1=YES; 0=NO
  0x70 D_DP_BN_ALU_CFG reset 0x0 (reset mask 0x3F0001) — Source type and shifter value of BN ALU
    [13:8] BN_ALU_SHIFT_VALUE
    [0] BN_ALU_SRC
      0=REG; 1=MEM
  0x74 D_DP_BN_ALU_SRC_VALUE reset 0x0 — Operand value of BN ALU
    [15:0] BN_ALU_OPERAND
  0x78 D_DP_BN_MUL_CFG reset 0x0 (reset mask 0xFF0001) — Source type and shifter value of BN MUL
    [15:8] BN_MUL_SHIFT_VALUE
    [0] BN_MUL_SRC
      0=REG; 1=MEM
  0x7C D_DP_BN_MUL_SRC_VALUE reset 0x0 — Operand value of BN MUL
    [15:0] BN_MUL_OPERAND
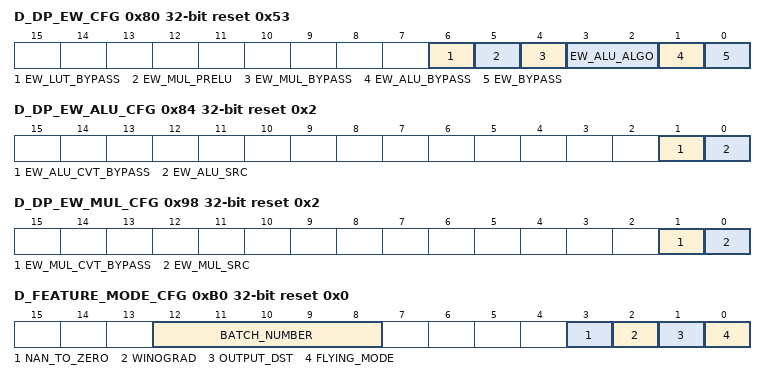
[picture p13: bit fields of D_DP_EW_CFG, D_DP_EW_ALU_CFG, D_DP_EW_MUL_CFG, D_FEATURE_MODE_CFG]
  0x80 D_DP_EW_CFG reset 0x53 — Configurations of EW module: bypass, algorithm, etc.
    [6] EW_LUT_BYPASS
      1=YES; 0=NO
    [5] EW_MUL_PRELU
      1=YES; 0=NO
    [4] EW_MUL_BYPASS
      1=YES; 0=NO
    [3:2] EW_ALU_ALGO
      2=SUM; 1=MIN; 0=MAX
    [1] EW_ALU_BYPASS
      1=YES; 0=NO
    [0] EW_BYPASS
      1=YES; 0=NO
  0x84 D_DP_EW_ALU_CFG reset 0x2 — Source type and bypass control of EW ALU
    [1] EW_ALU_CVT_BYPASS
      1=YES; 0=NO
    [0] EW_ALU_SRC
      0=REG; 1=MEM
  0x88 D_DP_EW_ALU_SRC_VALUE reset 0x0 — Operand value of EW ALU
    [31:0] EW_ALU_OPERAND
  0x8C D_DP_EW_ALU_CVT_OFFSET_VALUE reset 0x0 — Converter offset of EW ALU
    [31:0] EW_ALU_CVT_OFFSET
  0x90 D_DP_EW_ALU_CVT_SCALE_VALUE reset 0x0 — Converter scale of EW ALU
    [15:0] EW_ALU_CVT_SCALE
  0x94 D_DP_EW_ALU_CVT_TRUNCATE_VALUE reset 0x0 — Converter truncate of EW ALU
    [5:0] EW_ALU_CVT_TRUNCATE
  0x98 D_DP_EW_MUL_CFG reset 0x2 — Source type and bypass control of EW MUL
    [1] EW_MUL_CVT_BYPASS
      1=YES; 0=NO
    [0] EW_MUL_SRC
      0=REG; 1=MEM
  0x9C D_DP_EW_MUL_SRC_VALUE reset 0x0 — Operand value of EW MUL
    [31:0] EW_MUL_OPERAND
  0xA0 D_DP_EW_MUL_CVT_OFFSET_VALUE reset 0x0 — Converter offset of EW MUL
    [31:0] EW_MUL_CVT_OFFSET
  0xA4 D_DP_EW_MUL_CVT_SCALE_VALUE reset 0x0 — Converter scale of EW MUL
    [15:0] EW_MUL_CVT_SCALE
  0xA8 D_DP_EW_MUL_CVT_TRUNCATE_VALUE reset 0x0 — Converter truncate of EW MUL
    [5:0] EW_MUL_CVT_TRUNCATE
  0xAC D_DP_EW_TRUNCATE_VALUE reset 0x0 — Truncate of EW
    [9:0] EW_TRUNCATE
  0xB0 D_FEATURE_MODE_CFG reset 0x0 (reset mask 0x1F000F) — Operation configuration: flying mode, output destination, Direct or Winograd mode, flush NaN to zero, batch number.
    [12:8] BATCH_NUMBER
    [3] NAN_TO_ZERO
      1=ENABLE; 0=DISABLE
    [2] WINOGRAD
      1=ON; 0=OFF
    [1] OUTPUT_DST
      0=MEM; 1=PDP
    [0] FLYING_MODE
      1=ON; 0=OFF
  0xB4 D_DST_DMA_CFG reset 0x0 — Destination RAM type
    [0] DST_RAM_TYPE
      0=CV; 1=MC
  0xB8 D_DST_BATCH_STRIDE reset 0x0 — Stride of output cubes in batch mode
    [31:0] DST_BATCH_STRIDE
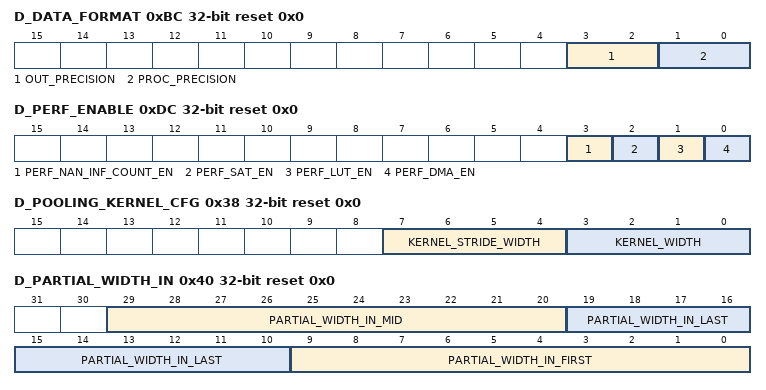
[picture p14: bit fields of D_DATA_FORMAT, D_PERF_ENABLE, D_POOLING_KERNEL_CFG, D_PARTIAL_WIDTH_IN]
  0xBC D_DATA_FORMAT reset 0x0 — Data precision
    [3:2] OUT_PRECISION
      2=FP16; 1=INT16; 0=INT8
    [1:0] PROC_PRECISION
      2=FP16; 1=INT16; 0=INT8
  0xC0 D_CVT_OFFSET reset 0x0 — Output converter offset
    [31:0] CVT_OFFSET
  0xC4 D_CVT_SCALE reset 0x0 — Output converter scale
    [15:0] CVT_SCALE
  0xC8 D_CVT_SHIFT reset 0x0 — Output converter shifter value
    [5:0] CVT_SHIFT
  0xCC D_STATUS ro reset 0x0 — Output of equal mode
    [0] STATUS_UNEQUAL
  0xD0 D_STATUS_NAN_INPUT_NUM ro reset 0x0 — Input NaN element number
    [31:0] STATUS_NAN_INPUT_NUM
  0xD4 D_STATUS_INF_INPUT_NUM ro reset 0x0 — Input Infinity element number
    [31:0] STATUS_INF_INPUT_NUM
  0xD8 D_STATUS_NAN_OUTPUT_NUM ro reset 0x0 — Output NaN element number
    [31:0] STATUS_NAN_OUTPUT_NUM
  0xDC D_PERF_ENABLE reset 0x0 — Enable/Disable performance counting
    [all] fields
      1=YES; 0=NO
    [3] PERF_NAN_INF_COUNT_EN
    [2] PERF_SAT_EN
    [1] PERF_LUT_EN
    [0] PERF_DMA_EN
  0xE0 D_PERF_WDMA_WRITE_STALL ro reset 0x0 — Count stall cycles of write DMA for one layer
    [31:0] WDMA_STALL
  0xE4 D_PERF_LUT_UFLOW ro reset 0x0 — Element number of both table underflow
    [31:0] LUT_UFLOW
  0xE8 D_PERF_LUT_OFLOW ro reset 0x0 — Element number of both table overflow
    [31:0] LUT_OFLOW
  0xEC D_PERF_OUT_SATURATION ro reset 0x0 — Element number of both table saturation
    [31:0] OUT_SATURATION
  0xF0 D_PERF_LUT_HYBRID ro reset 0x0 — Element number of both hit, or both miss situation that element underflow one table and at the same time overflow the other.
    [31:0] LUT_HYBRID
  0xF4 D_PERF_LUT_LE_HIT ro reset 0x0 — Element number of only LE table hit
    [31:0] LUT_LE_HIT
  0xF8 D_PERF_LUT_LO_HIT ro reset 0x0 — Element number of only LO table hit
    [31:0] LUT_LO_HIT
0xA000 PDP_RDMA group
  0x00 S_STATUS ro reset 0x0 (reset mask 0xC0000000) — Idle status of two register groups
    fields as CMAC_A.S_STATUS
  0x04 S_POINTER reset 0x0 (reset mask 0x80000000) — Pointer for CSB master and data path to access groups
    fields as CMAC_A.S_POINTER
  0x08 D_OP_ENABLE reset 0x0 — Set it to 1 to kick off operation for current register group
    [0] OP_EN
      1=ENABLE; 0=DISABLE
  0x0C D_DATA_CUBE_IN_WIDTH reset 0x0
    [12:0] CUBE_IN_WIDTH
  0x10 D_DATA_CUBE_IN_HEIGHT reset 0x0
    [12:0] CUBE_IN_HEIGHT
  0x14 D_DATA_CUBE_IN_CHANNEL reset 0x0
    [12:0] CUBE_IN_CHANNEL
  0x18 D_FLYING_MODE reset 0x0
    [0] FLYING_MODE
      1=ON; 0=OFF
  0x1C D_SRC_BASE_ADDR_LOW reset 0x0
    [31:0] SRC_BASE_ADDR_LOW
  0x20 D_SRC_BASE_ADDR_HIGH reset 0x0
    [31:0] SRC_BASE_ADDR_HIGH
  0x24 D_SRC_LINE_STRIDE reset 0x0
    [31:0] SRC_LINE_STRIDE
  0x28 D_SRC_SURFACE_STRIDE reset 0x0
    [31:0] SRC_SURFACE_STRIDE
  0x2C D_SRC_RAM_CFG reset 0x0
    [0] SRC_RAM_TYPE
      0=CV; 1=MC
  0x30 D_DATA_FORMAT reset 0x0
    [1:0] INPUT_DATA
      2=FP16; 1=INT16; 0=INT8
  0x34 D_OPERATION_MODE_CFG reset 0x0
    [7:0] SPLIT_NUM
  0x38 D_POOLING_KERNEL_CFG reset 0x0
    [7:4] KERNEL_STRIDE_WIDTH
    [3:0] KERNEL_WIDTH
      {v}=WIDTH_{v+1} (v=0..7)
  0x3C D_POOLING_PADDING_CFG reset 0x0
    [3:0] PAD_WIDTH
  0x40 D_PARTIAL_WIDTH_IN reset 0x0 (reset mask 0xFFC03FF0)
    [29:20] PARTIAL_WIDTH_IN_MID, [19:10] PARTIAL_WIDTH_IN_LAST, [9:0] PARTIAL_WIDTH_IN_FIRST
  0x44 D_PERF_ENABLE reset 0x0
    [0] DMA_EN
      1=ENABLE; 0=DISABLE
  0x48 D_PERF_READ_STALL ro reset 0x0
    [31:0] PERF_READ_STALL
  0x4C D_CYA reset 0x0
    [31:0] D_CYA — CYA register
0xB000 PDP group
  0x00 S_STATUS ro reset 0x0 (reset mask 0xC0000000) — Idle status of two register groups
    fields as CMAC_A.S_STATUS
  0x04 S_POINTER reset 0x0 (reset mask 0x80000000) — Pointer for CSB master and data path to access groups
    fields as CMAC_A.S_POINTER
  0x08 D_OP_ENABLE reset 0x0 — Set it to 1 to kick off operation for current register group
    [0] OP_EN
      1=ENABLE; 0=DISABLE
  0x0C D_DATA_CUBE_IN_WIDTH reset 0x0 — Input data cube’s width
    [12:0] CUBE_IN_WIDTH
  0x10 D_DATA_CUBE_IN_HEIGHT reset 0x0 — Input data cube’s height
    [12:0] CUBE_IN_HEIGHT
  0x14 D_DATA_CUBE_IN_CHANNEL reset 0x0 — Input data cube’s channel
    [12:0] CUBE_IN_CHANNEL
  0x18 D_DATA_CUBE_OUT_WIDTH reset 0x0 — Output data cube’s width
    [12:0] CUBE_OUT_WIDTH
  0x1C D_DATA_CUBE_OUT_HEIGHT reset 0x0 — Output data cube’s height
    [12:0] CUBE_OUT_HEIGHT
  0x20 D_DATA_CUBE_OUT_CHANNEL reset 0x0 — Output data cube’s channel
    [12:0] CUBE_OUT_CHANNEL
  0x24 D_OPERATION_MODE_CFG reset 0x0 (reset mask 0xFF0013) — Split number
    [15:8] SPLIT_NUM
    [4] FLYING_MODE
    [1:0] POOLING_METHOD
      0=AVERAGE; 1=MAX; 2=MIN
  0x28 D_NAN_FLUSH_TO_ZERO reset 0x0 — Option to flush input NaN to zero
    [0] NAN_TO_ZERO
      1=ENABLE; 0=DISABLE
  0x2C D_PARTIAL_WIDTH_IN reset 0x0 (reset mask 0xFFC03FF0) — Partial width for first, last and middle partitions of input cube
    fields as PDP_RDMA.D_PARTIAL_WIDTH_IN
  0x30 D_PARTIAL_WIDTH_OUT reset 0x0 (reset mask 0xFFC03FF0) — Partial width for first, last and middle partitions of output cube
    [29:20] PARTIAL_WIDTH_OUT_MID, [19:10] PARTIAL_WIDTH_OUT_LAST, [9:0] PARTIAL_WIDTH_OUT_FIRST
  0x34 D_POOLING_KERNEL_CFG reset 0x0 (reset mask 0xFF000F00) — Kernel width and kernel stride
    [23:20] KERNEL_STRIDE_HEIGHT
    [19:16] KERNEL_STRIDE_WIDTH
    [11:8] KERNEL_HEIGHT
      {v}=HEIGHT_{v+1} (v=0..7)
    [3:0] KERNEL_WIDTH
      {v}=WIDTH_{v+1} (v=0..7)
  0x38 D_RECIP_KERNEL_WIDTH reset 0x0 — Reciprocal of pooling kernel width, set to actual value * (2^16) when INT8/INT16 format enabled. and set to actual value for fp16 precision mode with fp17 data format.
    [16:0] RECIP_KERNEL_WIDTH
  0x3C D_RECIP_KERNEL_HEIGHT reset 0x0 — Reciprocal of pooling kernel height, set to actual value * (2^16) when INT8/INT16 format enabled. and set to actual value for fp16 precision mode with fp17 data format.
    [16:0] RECIP_KERNEL_HEIGHT
  0x40 D_POOLING_PADDING_CFG reset 0x0 (reset mask 0x770077) — Left/right/top/bottom padding size
    [14:12] PAD_BOTTOM, [10:8] PAD_RIGHT, [6:4] PAD_TOP, [2:0] PAD_LEFT
  {0x40+4j} D_POOLING_PADDING_VALUE_{j}_CFG reset 0x0 (j=1..7) — Padding_value*{j}
    [18:0] PAD_VALUE_{j}X
  0x60 D_SRC_BASE_ADDR_LOW reset 0x0 — Lower 32bits of input data address
    [31:0] SRC_BASE_ADDR_LOW
  0x64 D_SRC_BASE_ADDR_HIGH reset 0x0 — Higher 32bits of input data address when axi araddr is 64bits
    [31:0] SRC_BASE_ADDR_HIGH
  0x68 D_SRC_LINE_STRIDE reset 0x0 — Line stride of input cube
    [31:0] SRC_LINE_STRIDE
  0x6C D_SRC_SURFACE_STRIDE reset 0x0 — Surface stride of input cube
    [31:0] SRC_SURFACE_STRIDE
  0x70 D_DST_BASE_ADDR_LOW reset 0x0 — Lower 32bits of output data address
    [31:0] DST_BASE_ADDR_LOW
  0x74 D_DST_BASE_ADDR_HIGH reset 0x0 — Higher 32bits of output data address when axi awaddr is 64bits
    [31:0] DST_BASE_ADDR_HIGH
  0x78 D_DST_LINE_STRIDE reset 0x0 — Line stride of output cube
    [31:0] DST_LINE_STRIDE
  0x7C D_DST_SURFACE_STRIDE reset 0x0 — Surface stride of output cube
    [31:0] DST_SURFACE_STRIDE
  0x80 D_DST_RAM_CFG reset 0x0 — RAM type of destination cube
    [0] DST_RAM_TYPE
      0=CV; 1=MC
  0x84 D_DATA_FORMAT reset 0x0 — Precision of input data
    [1:0] INPUT_DATA
      2=FP16; 1=INT16; 0=INT8
  0x88 D_INF_INPUT_NUM ro reset 0x0 — Input infinity element number
    [31:0] INF_INPUT_NUM
  0x8C D_NAN_INPUT_NUM ro reset 0x0 — Input NaN element number
    [31:0] NAN_INPUT_NUM
  0x90 D_NAN_OUTPUT_NUM ro reset 0x0 — Output NaN element number
    [31:0] NAN_OUTPUT_NUM
  0x94 D_PERF_ENABLE reset 0x0 — Enable/disable performance counting
    [0] DMA_EN
      1=ENABLE; 0=DISABLE
  0x98 D_PERF_WRITE_STALL ro reset 0x0 — Counting stalls of write requests
    [31:0] PERF_WRITE_STALL
  0x9C D_CYA reset 0x0
    [31:0] D_CYA — CYA register
